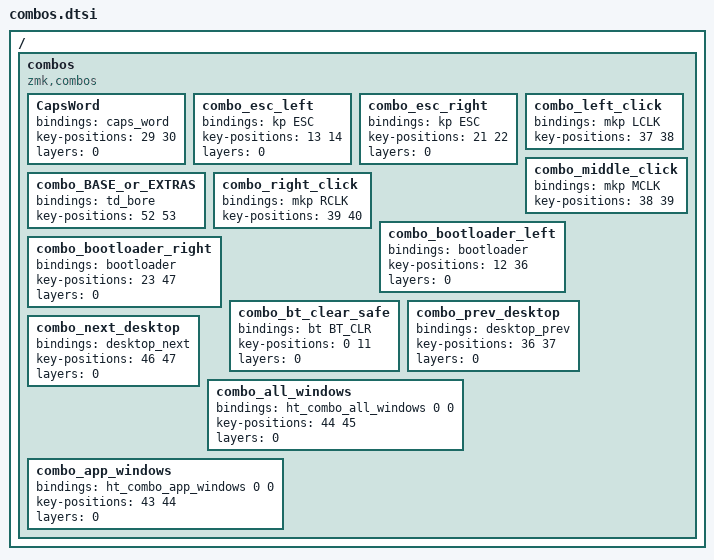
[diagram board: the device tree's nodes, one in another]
/* --- KEY ID LAYOUT --- */
// ╭──────┬──────┬──────┬──────┬──────┬──────╮  ╭──────┬──────┬──────┬──────┬──────┬──────╮
//    00     01     02     03    04      05        06     07     08     09     10     11
// ├──────┼──────┼──────┼──────┼──────┼──────┤  ├──────┼──────┼──────┼──────┼──────┼──────┤
//    12     13     14     15    16      17        18     19     20     21     22     23
// ├──────┼──────┼──────┼──────┼──────┼──────┤  ├──────┼──────┼──────┼──────┼──────┼──────┤
//    24     25     26     27    28      29        30     31     32     33     34     35
// ├──────┼──────┼──────┼──────┼──────┼──────┤  ├──────┼──────┼──────┼──────┼──────┼──────┤
//    36     37     38     39    40      41        42     43     44     45     46     47
// ╰──────┴──────┴──────┼──────┼──────┼──────┼──────┼──────╮  ╭──────┼──────┼──────┴──────┴──────┴──────╯
//                        48     49     50     51     52        53     54     55
//                      ╰──────┴──────┴──────┴──────┴──────╯  ╰──────┴──────┴──────╯

/ {
    combos {
        compatible = "zmk,combos";

        CapsWord {
            bindings = <&caps_word>;
            key-positions = <29 30>;
            layers = <0>;
        };

        combo_esc_left {
            bindings = <&kp ESC>;
            key-positions = <13 14>;
            layers = <0>;
        };

        combo_esc_right {
            bindings = <&kp ESC>;
            key-positions = <21 22>;
            layers = <0>;
        };

        combo_BASE_or_EXTRAS {
            bindings = <&td_bore>;
            key-positions = <52 53>;
        };
        
        combo_left_click {
            bindings = <&mkp LCLK>;
            key-positions = <37 38>;
        };
        
        combo_middle_click {
            bindings = <&mkp MCLK>;
            key-positions = <38 39>;
        };

        combo_right_click {
            bindings = <&mkp RCLK>;
            key-positions = <39 40>;
        };

        combo_bootloader_left {
            bindings = <&bootloader>;
            key-positions = <12 36>;
            layers = <0>;
        };

        combo_bootloader_right {
            bindings = <&bootloader>;
            key-positions = <23 47>;
            layers = <0>;
        };

        combo_bt_clear_safe {
            bindings = <&bt BT_CLR>;
            key-positions = <0 11>;
            layers = <0>;
        };

        combo_prev_desktop {
            bindings = <&desktop_prev>;
            key-positions = <36 37>;
            layers = <0>;
        };

        combo_next_desktop {
            bindings = <&desktop_next>;
            key-positions = <46 47>;
            layers = <0>;
        };

        combo_all_windows {
            bindings = <&ht_combo_all_windows 0 0>;
            key-positions = <44 45>;
            layers = <0>;
        };

        combo_app_windows {
            // KDE Present Windows (current app/window class).
            bindings = <&ht_combo_app_windows 0 0>;
            key-positions = <43 44>;
            layers = <0>;
        };
    };
};
